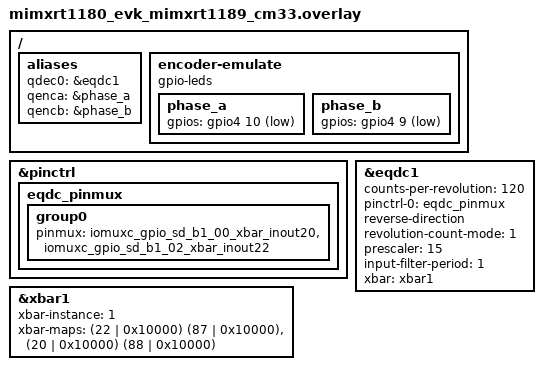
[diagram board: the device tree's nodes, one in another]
/*
 * Copyright 2026 NXP
 *
 * SPDX-License-Identifier: Apache-2.0
 */

/ {
	aliases {
		qdec0 = &eqdc1;
		qenca = &phase_a;
		qencb = &phase_b;
	};

	encoder-emulate {
		compatible = "gpio-leds";

		phase_a: phase_a {
			gpios = <&gpio4 10 GPIO_ACTIVE_LOW>;
		};

		phase_b: phase_b {
			gpios = <&gpio4 9 GPIO_ACTIVE_LOW>;
		};
	};
};

/* Wire J44 2 <-> J44 6 and J44 4 <-> J44 8 */
&pinctrl {
	eqdc_pinmux: eqdc_pinmux {
		group0 {
			pinmux = <&iomuxc_gpio_sd_b1_00_xbar_inout20>,
				 <&iomuxc_gpio_sd_b1_02_xbar_inout22>;
		};
	};
};

&eqdc1 {
	status = "okay";
	counts-per-revolution = <120>;
	pinctrl-0 = <&eqdc_pinmux>;
	pinctrl-names = "default";
	reverse-direction;
	revolution-count-mode = <1>;
	prescaler = <15>;
	input-filter-period = <1>;
	xbar = <&xbar1>;
};

&xbar1 {
	status = "okay";
	xbar-instance = <1>;
	xbar-maps =
		    /* kXBAR1_InputIomuxXbarInout22 <-> kXBARA1_OutputEnc1PhaseAInput */
		    <(22 | 0x10000) (87 | 0x10000)>,
		    /* kXBAR1_InputIomuxXbarInout20 <-> kXBARA1_OutputEnc1PhaseBInput */
		    <(20 | 0x10000) (88 | 0x10000)>;
};
